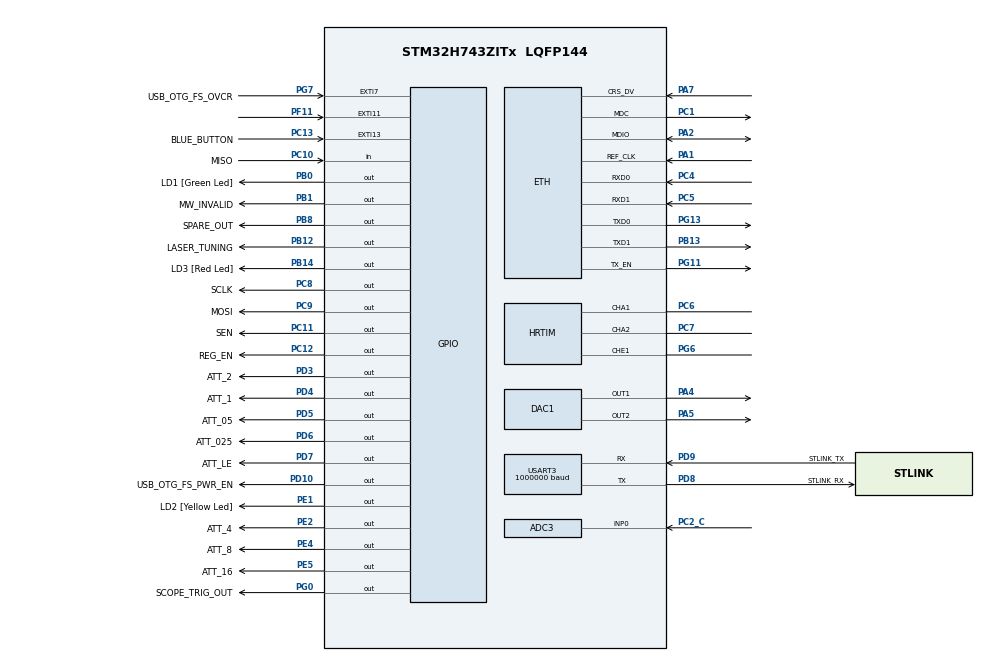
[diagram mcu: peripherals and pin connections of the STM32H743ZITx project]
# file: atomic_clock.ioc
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ADC3.Channel-0\#ChannelRegularConversion=ADC_CHANNEL_0
ADC3.ContinuousConvMode=DISABLE
ADC3.LeftBitShift=ADC_LEFTBITSHIFT_NONE
ADC3.NbrOfConversionFlag=1
ADC3.OffsetNumber-0\#ChannelRegularConversion=ADC_OFFSET_NONE
ADC3.OffsetSignedSaturation-0\#ChannelRegularConversion=DISABLE
ADC3.Rank-0\#ChannelRegularConversion=1
ADC3.SamplingTime-0\#ChannelRegularConversion=ADC_SAMPLETIME_1CYCLE_5
CORTEX_M7.AccessPermission-Cortex_Memory_Protection_Unit_Region1_Settings=MPU_REGION_FULL_ACCESS
CORTEX_M7.AccessPermission-Cortex_Memory_Protection_Unit_Region2_Settings=MPU_REGION_FULL_ACCESS
CORTEX_M7.BaseAddress-Cortex_Memory_Protection_Unit_Region1_Settings=0x30020000
CORTEX_M7.BaseAddress-Cortex_Memory_Protection_Unit_Region2_Settings=0x30040000
CORTEX_M7.CPU_DCache=Enabled
CORTEX_M7.CPU_ICache=Enabled
CORTEX_M7.DisableExec-Cortex_Memory_Protection_Unit_Region0_Settings=MPU_INSTRUCTION_ACCESS_DISABLE
CORTEX_M7.DisableExec-Cortex_Memory_Protection_Unit_Region1_Settings=MPU_INSTRUCTION_ACCESS_DISABLE
CORTEX_M7.DisableExec-Cortex_Memory_Protection_Unit_Region2_Settings=MPU_INSTRUCTION_ACCESS_DISABLE
CORTEX_M7.Enable-Cortex_Memory_Protection_Unit_Region0_Settings=MPU_REGION_ENABLE
CORTEX_M7.Enable-Cortex_Memory_Protection_Unit_Region1_Settings=MPU_REGION_ENABLE
CORTEX_M7.Enable-Cortex_Memory_Protection_Unit_Region2_Settings=MPU_REGION_ENABLE
CORTEX_M7.IsBufferable-Cortex_Memory_Protection_Unit_Region2_Settings=MPU_ACCESS_BUFFERABLE
CORTEX_M7.IsShareable-Cortex_Memory_Protection_Unit_Region0_Settings=MPU_ACCESS_SHAREABLE
CORTEX_M7.IsShareable-Cortex_Memory_Protection_Unit_Region2_Settings=MPU_ACCESS_SHAREABLE
CORTEX_M7.MPU_Control=MPU_PRIVILEGED_DEFAULT
CORTEX_M7.Size-Cortex_Memory_Protection_Unit_Region0_Settings=MPU_REGION_SIZE_4GB
CORTEX_M7.Size-Cortex_Memory_Protection_Unit_Region1_Settings=MPU_REGION_SIZE_128KB
CORTEX_M7.Size-Cortex_Memory_Protection_Unit_Region2_Settings=MPU_REGION_SIZE_512B
CORTEX_M7.SubRegionDisable-Cortex_Memory_Protection_Unit_Region0_Settings=0x87
CORTEX_M7.TypeExtField-Cortex_Memory_Protection_Unit_Region1_Settings=MPU_TEX_LEVEL1
CORTEX_M7.default_mode_Activation=0
DAC1.DAC_Channel-DAC_OUT1=DAC_CHANNEL_1
DAC1.DAC_Channel-DAC_OUT2=DAC_CHANNEL_2
ETH.MediaInterface=HAL_ETH_RMII_MODE
HRTIM.CompareUnit1-Output_TA1TA2=HRTIM_COMPAREUNIT_1
HRTIM.CompareUnit1-Output_TE1=HRTIM_COMPAREUNIT_1
HRTIM.CompareUnit2-Output_TA1TA2=HRTIM_COMPAREUNIT_2
HRTIM.CompareUnit2-Output_TE1=HRTIM_COMPAREUNIT_2
HRTIM.CompareUnit3-Output_TA1TA2=HRTIM_COMPAREUNIT_3
HRTIM.CompareUnit3-Output_TE1=HRTIM_COMPAREUNIT_3
HRTIM.CompareUnit4-Output_TE1=HRTIM_COMPAREUNIT_4
HRTIM.CompareValue1-Output_TA1TA2=PUMP_WIDTH
HRTIM.CompareValue1-Output_TE1=PUMP_WIDTH+MICROWAVE_DELAY
HRTIM.CompareValue2-Output_TA1TA2=PUMP_WIDTH+(2*MICROWAVE_DELAY)+(2*MICROWAVE_WIDTH)+RAMSEY_TIME
HRTIM.CompareValue2-Output_TE1=PUMP_WIDTH+MICROWAVE_DELAY+MICROWAVE_WIDTH
HRTIM.CompareValue3-Output_TA1TA2=PUMP_WIDTH+(2*MICROWAVE_DELAY)+(2*MICROWAVE_WIDTH)+RAMSEY_TIME+PROBE_WIDTH
HRTIM.CompareValue3-Output_TE1=PUMP_WIDTH+MICROWAVE_DELAY+MICROWAVE_WIDTH+RAMSEY_TIME
HRTIM.CompareValue4-Output_TE1=PUMP_WIDTH+MICROWAVE_DELAY+MICROWAVE_WIDTH+RAMSEY_TIME+MICROWAVE_WIDTH
HRTIM.IdleLevel1-Output_TA1TA2=HRTIM_OUTPUTIDLELEVEL_ACTIVE
HRTIM.IdleLevel2-Output_TA1TA2=HRTIM_OUTPUTIDLELEVEL_ACTIVE
HRTIM.InterruptRequests1-Output_TA1TA2=HRTIM_TIM_IT_CMP3
HRTIM.InterruptRequests1-Output_TE1=HRTIM_TIM_IT_CMP2
HRTIM.InterruptRequests2-Output_TA1TA2=HRTIM_TIM_IT_REP
HRTIM.InterruptRequests2-Output_TE1=HRTIM_TIM_IT_CMP3
HRTIM.ModeTimeBase-Output_TE1=HRTIM_MODE_CONTINUOUS
HRTIM.NumberInterruptRequests-Output_TA1TA2=2
HRTIM.NumberInterruptRequests-Output_TE1=2
HRTIM.NumberResetSource1-Output_TA1TA2=2
HRTIM.NumberResetSource1-Output_TE1=2
HRTIM.NumberResetSource2_TA=1
HRTIM.NumberSetSource1-Output_TA1TA2=2
HRTIM.NumberSetSource1-Output_TE1=2
HRTIM.NumberSetSource2_TA=1
HRTIM.Periode_TA=PUMP_WIDTH+(2*MICROWAVE_DELAY)+(2*MICROWAVE_WIDTH)+RAMSEY_TIME+PROBE_WIDTH+POP_CYCLE_DELAY
HRTIM.Periode_TE=PUMP_WIDTH+(2*MICROWAVE_DELAY)+(2*MICROWAVE_WIDTH)+RAMSEY_TIME+PROBE_WIDTH+POP_CYCLE_DELAY
HRTIM.Polarity1-Output_TA1TA2=HRTIM_OUTPUTPOLARITY_LOW
HRTIM.Polarity2-Output_TA1TA2=HRTIM_OUTPUTPOLARITY_LOW
HRTIM.PrescalerRatio_TA=HRTIM_PRESCALERRATIO_DIV4
HRTIM.PrescalerRatio_TE=HRTIM_PRESCALERRATIO_DIV4
HRTIM.ResetOutput1_Source1-Output_TA1TA2=HRTIM_OUTPUTRESET_TIMCMP2
HRTIM.ResetOutput1_Source1-Output_TE1=HRTIM_OUTPUTRESET_TIMCMP2
HRTIM.ResetOutput1_Source2-Output_TA1TA2=HRTIM_OUTPUTRESET_TIMPER
HRTIM.ResetOutput1_Source2-Output_TE1=HRTIM_OUTPUTRESET_TIMCMP4
HRTIM.ResetOutput2_Source1-Output_TA1TA2=HRTIM_OUTPUTRESET_TIMCMP2
HRTIM.SetOutput1_Source1-Output_TA1TA2=HRTIM_OUTPUTSET_TIMCMP1
HRTIM.SetOutput1_Source1-Output_TE1=HRTIM_OUTPUTSET_TIMCMP1
HRTIM.SetOutput1_Source2-Output_TA1TA2=HRTIM_OUTPUTSET_TIMCMP3
HRTIM.SetOutput1_Source2-Output_TE1=HRTIM_OUTPUTSET_TIMCMP3
HRTIM.SetOutput2_Source1-Output_TA1TA2=HRTIM_OUTPUTSET_TIMCMP3
HRTIM.SyncOptions=HRTIM_SYNCOPTION_NONE
LPTIM1.ClockPrescaler=LPTIM_PRESCALER_DIV32
LWIP.BSP.number=1
LWIP.GATEWAY_ADDRESS=192.168.001.001
LWIP.IP_ADDRESS=192.168.001.010
LWIP.LWIP_DHCP=0
LWIP.LWIP_RAM_HEAP_POINTER=0x30020000
LWIP.MEM_SIZE=131048
LWIP.NETMASK_ADDRESS=255.255.000.000
LWIP.TCP_MSS=1460
LWIP.TCP_SND_BUF=5840
LWIP.TCP_SND_QUEUELEN=16
LWIP.Version=v2.1.2_Cube
LWIP0.BSP.STBoard=false
LWIP0.BSP.api=BSP_COMPONENT_DRIVER
LWIP0.BSP.component=LAN8742
LWIP0.BSP.instance=LAN8742
LWIP0.BSP.name=Driver_PHY
LWIP0.BSP.semaphore=S_LAN8742
LWIP0.BSP.solution=LAN8742
Mcu.Family=STM32H7
Mcu.Name=STM32H743ZITx
Mcu.Package=LQFP144
Mcu.UserConstants=POP_CYCLE_DELAY,31250;MICROWAVE_WIDTH,1563;PROBE_WIDTH,625;MICROWAVE_DELAY,312;PUMP_WIDTH,1563;RAMSEY_TIME,12500
NVIC.ADC3_IRQn=true\:0\:0\:false\:false\:true\:true\:true\:true
NVIC.EXTI15_10_IRQn=true\:0\:0\:false\:false\:true\:true\:true\:true
NVIC.HRTIM1_TIMA_IRQn=true\:0\:0\:true\:false\:true\:true\:true\:true
NVIC.HRTIM1_TIME_IRQn=true\:0\:0\:false\:false\:true\:true\:true\:true
NVIC.LPTIM1_IRQn=true\:0\:0\:true\:false\:true\:true\:true\:true
NVIC.PriorityGroup=NVIC_PRIORITYGROUP_4
PA1.Mode=RMII
PA1.Signal=ETH_REF_CLK
PA11.Signal=USB_OTG_FS_DM
PA12.Signal=USB_OTG_FS_DP
PA2.Mode=RMII
PA2.Signal=ETH_MDIO
PA4.Signal=COMP_DAC11_group
PA5.Signal=COMP_DAC12_group
PA7.Mode=RMII
PA7.Signal=ETH_CRS_DV
PA8.Signal=USB_OTG_FS_SOF
PA9.Signal=USB_OTG_FS_VBUS
PB0.GPIO_Label=LD1 [Green Led]
PB0.Signal=GPIO_Output
PB1.GPIO_Label=MW_INVALID
PB1.Signal=GPIO_Output
PB12.GPIO_Label=LASER_TUNING
PB12.Signal=GPIO_Output
PB13.Mode=RMII
PB13.Signal=ETH_TXD1
PB14.GPIO_Label=LD3 [Red Led]
PB14.Signal=GPIO_Output
PB8.GPIO_Label=SPARE_OUT
PB8.Signal=GPIO_Output
PC1.Mode=RMII
PC1.Signal=ETH_MDC
PC10.GPIO_Label=MISO
PC10.GPIO_PuPd=GPIO_NOPULL
PC10.Signal=GPIO_Input
PC11.GPIO_Label=SEN
PC11.GPIO_PuPd=GPIO_PULLDOWN
PC11.PinState=GPIO_PIN_SET
PC11.Signal=GPIO_Output
PC12.GPIO_Label=REG_EN
PC12.GPIO_PuPd=GPIO_PULLDOWN
PC12.Signal=GPIO_Output
PC13.GPIO_Label=BLUE_BUTTON
PC13.GPIO_ModeDefaultEXTI=GPIO_MODE_IT_RISING
PC13.Signal=GPXTI13
PC14-OSC32_IN\ (OSC32_IN).Mode=LSE-External-Oscillator
PC14-OSC32_IN\ (OSC32_IN).Signal=RCC_OSC32_IN
PC15-OSC32_OUT\ (OSC32_OUT).Mode=LSE-External-Oscillator
PC15-OSC32_OUT\ (OSC32_OUT).Signal=RCC_OSC32_OUT
PC2_C.Mode=IN0-Single-Ended
PC2_C.Signal=ADC3_INP0
PC4.Mode=RMII
PC4.Signal=ETH_RXD0
PC5.Mode=RMII
PC5.Signal=ETH_RXD1
PC6.GPIO_PuPd=GPIO_NOPULL
PC6.GPIO_Speed_High_Default=GPIO_SPEED_FREQ_VERY_HIGH
PC6.Mode=Output_TA1TA2
PC6.Signal=HRTIM_CHA1
PC7.Mode=Output_TA1TA2
PC7.Signal=HRTIM_CHA2
PC8.GPIO_Label=SCLK
PC8.GPIO_PuPd=GPIO_PULLDOWN
PC8.Signal=GPIO_Output
PC9.GPIO_Label=MOSI
PC9.GPIO_PuPd=GPIO_PULLDOWN
PC9.Signal=GPIO_Output
PD10.GPIO_Label=USB_OTG_FS_PWR_EN
PD10.Signal=GPIO_Output
PD3.GPIO_Label=ATT_2
PD3.PinState=GPIO_PIN_SET
PD3.Signal=GPIO_Output
PD4.GPIO_Label=ATT_1
PD4.PinState=GPIO_PIN_SET
PD4.Signal=GPIO_Output
PD5.GPIO_Label=ATT_05
PD5.PinState=GPIO_PIN_SET
PD5.Signal=GPIO_Output
PD6.GPIO_Label=ATT_025
PD6.PinState=GPIO_PIN_SET
PD6.Signal=GPIO_Output
PD7.GPIO_Label=ATT_LE
PD7.PinState=GPIO_PIN_SET
PD7.Signal=GPIO_Output
PD8.GPIO_Label=STLINK_RX
PD8.Mode=Asynchronous
PD8.Signal=USART3_TX
PD9.GPIO_Label=STLINK_TX
PD9.Mode=Asynchronous
PD9.Signal=USART3_RX
PE1.GPIO_Label=LD2 [Yellow Led]
PE1.PinAttribute=Free
PE1.Signal=GPIO_Output
PE2.GPIO_Label=ATT_4
PE2.PinState=GPIO_PIN_SET
PE2.Signal=GPIO_Output
PE4.GPIO_Label=ATT_8
PE4.PinState=GPIO_PIN_SET
PE4.Signal=GPIO_Output
PE5.GPIO_Label=ATT_16
PE5.PinState=GPIO_PIN_SET
PE5.Signal=GPIO_Output
PF11.Signal=GPXTI11
PG0.GPIO_Label=SCOPE_TRIG_OUT
PG0.Signal=GPIO_Output
PG11.Mode=RMII
PG11.Signal=ETH_TX_EN
PG13.Mode=RMII
PG13.Signal=ETH_TXD0
PG6.GPIO_PuPd=GPIO_NOPULL
PG6.GPIO_Speed_High_Default=GPIO_SPEED_FREQ_VERY_HIGH
PG6.Mode=Output_TE1
PG6.Signal=HRTIM_CHE1
PG7.GPIO_Label=USB_OTG_FS_OVCR
PG7.Signal=GPXTI7
PH0-OSC_IN\ (PH0).Mode=HSE-External-Clock-Source
PH0-OSC_IN\ (PH0).Signal=RCC_OSC_IN
PH1-OSC_OUT\ (PH1).Signal=RCC_OSC_OUT
ProjectManager.HeapSize=0x200
ProjectManager.StackSize=0x400
ProjectManager.TargetToolchain=STM32CubeIDE
RCC.ADCFreq_Value=2405063.2911392404
RCC.APB1Freq_Value=100000000
RCC.APB2Freq_Value=6250000
RCC.APB3Freq_Value=100000000
RCC.APB4Freq_Value=100000000
RCC.CKPERSourceSelection=RCC_CLKPSOURCE_HSE
RCC.CSICalibrationValue=16
RCC.CortexFreq_Value=400000000
RCC.D2PPRE2=RCC_APB2_DIV16
RCC.DIVM1=1
RCC.DIVM2=1
RCC.DIVN1=80
RCC.DIVN2=19
RCC.DIVP2=79
RCC.DIVQ1=4
RCC.EnbaleCSS=true
RCC.FLatency-AdvancedSettings=FLASH_LATENCY_0
RCC.HCLKFreq_Value=100000000
RCC.HPRE=RCC_HCLK_DIV4
RCC.HSE_VALUE=10000000
RCC.HSICalibrationValue=32
RCC.LPTIM1CLockSelection=RCC_LPTIM1CLKSOURCE_LSE
RCC.LPTIM2CLockSelection=RCC_LPTIM2CLKSOURCE_LSE
RCC.PLL1_VCI_Range-AdvancedSettings=RCC_PLL1VCIRANGE_0
RCC.PLL1_VCO_SEL=RCC_PLL1VCOWIDE
RCC.PLL2FRACN=0
RCC.PLL2_VCI_Range-AdvancedSettings=RCC_PLL2VCIRANGE_0
RCC.PLL2_VCO_SEL-AdvancedSettings=RCC_PLL2VCOMEDIUM
RCC.PLL3FRACN=0
RCC.PLL3_VCI_Range-AdvancedSettings=RCC_PLL3VCIRANGE_0
RCC.PLL3_VCO_SEL-AdvancedSettings=RCC_PLL3VCOMEDIUM
RCC.PLLFRACN=0
RCC.PLLSourceVirtual=RCC_PLLSOURCE_HSE
RCC.PWR_Regulator_Voltage_Scale=PWR_REGULATOR_VOLTAGE_SCALE1
RCC.ProductRev=revV
RCC.SYSCLKFreq_VALUE=400000000
RCC.SYSCLKSource=RCC_SYSCLKSOURCE_PLLCLK
RCC.USBFreq_Value=200000000
SH.COMP_DAC11_group.0=DAC1_OUT1,DAC_OUT1
SH.COMP_DAC12_group.0=DAC1_OUT2,DAC_OUT2
TIM1.Prescaler=1249
TIM2.Prescaler=124
TIM3.Prescaler=124
TIM4.Prescaler=62499
TIM5.Prescaler=124
USART3.BaudRate=1000000
USART3.VirtualMode-Asynchronous=VM_ASYNC
VP_LPTIM1_VS_LPTIM_counterModeInternalClock.Mode=Counts__internal_clock_event_00
VP_LWIP_VS_Enabled.Mode=Enabled
VP_RCC_LSE.Mode=CRS SYNC Source LSE
VP_TIM1_VS_ClockSourceINT.Mode=Internal
VP_TIM2_VS_ClockSourceINT.Mode=Internal
VP_TIM3_VS_ClockSourceINT.Mode=Internal
VP_TIM4_VS_ClockSourceINT.Mode=Internal
VP_TIM5_VS_ClockSourceINT.Mode=Internal
board=NUCLEO-H743ZI2

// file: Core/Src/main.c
/* USER CODE BEGIN Header */
/**
 ******************************************************************************
 * @file           : main.c
 * @brief          : Main program body
 * @authors		   : Simon J. Bale and Stuart Kenny
 ******************************************************************************
 */
/* USER CODE END Header */
#include "main.h"
#include "lwip.h"

/* USER CODE BEGIN Includes */
#include "mw_gen.h"
//#include "laserlock.h"
#include <stdio.h>
#include <stdint.h>
#include <stdbool.h>
#include <string.h>
#include <math.h>

/* USER CODE END Includes */

/* USER CODE BEGIN PTD */
#ifdef ETHERNET_FOR_LDC501
extern struct netif gnetif;
#endif //ETHERNET_FOR_LDC501

/* USER CODE END PTD */

/* USER CODE BEGIN PD */

#define PUTCHAR_PROTOTYPE int __io_putchar(int ch)
//#define ETHERNET_FOR_LDC501
#define SYNTH_ENABLE
#define POP_START_PULSE
//#define QUANTIFY_ADC_NOISE
#define MW_VERBOSE
#define NO_SCOPE_SYNC 0
#define ADD_SCOPE_SYNC_TIME 0
#define DIRECT_ADC_TO_DAC

/* USER CODE END PD */

ADC_HandleTypeDef hadc3;

DAC_HandleTypeDef hdac1;

HRTIM_HandleTypeDef hhrtim;

LPTIM_HandleTypeDef hlptim1;

TIM_HandleTypeDef htim1;
TIM_HandleTypeDef htim2;
TIM_HandleTypeDef htim3;
TIM_HandleTypeDef htim4;
TIM_HandleTypeDef htim5;

UART_HandleTypeDef huart3;

/* USER CODE BEGIN PV */
static const uint32_t ERROR_LED_DELAY = 1000; // 100 ms

//extern SweepSettings const sweep_settings;
extern bool absorption_dip_locked;

extern uint32_t _siitcm;
extern uint32_t _sitcm;
extern uint32_t _eitcm;

static volatile bool mw_sweep_started = false;
volatile bool blue_button_status; //blue button state. 1 when pressed
//static bool last_pin_status; //previous blue button state
volatile uint16_t sample_count=0; //counts number of times the sample line drives the ADC trigger high, updated after conversion is complete
uint32_t POP_period_us=0; //length of POP cycle in us

static uint8_t MW_power = 0x2; // Initial MW power i.e. LO2GAIN
//3 is max, 0 is min, log scale with 2dB between points
//max is +5dBm output, min is -1dBm out.
//NOTE - these values are measured and not consistent with datasheet

/* ADC sample storage */
uint32_t adc_val, adc_averaged_val; //used to store adc3 readings (16-bit value in a 32-bit reg)
uint32_t adc_readings[ADC_SAMPLES]; //an array for the requisite number of samples
uint16_t adc_sample_no = 0; //for storing a rotating pointer to the array
uint32_t adc_readings_total = 0; //for storing the total of N samples
bool adc_average_updated = false; //allows polling without needing to compare previous values
uint32_t adc_polled_above = 0; //used to store adc3 readings
uint32_t adc_polled_below = 0; //used to store adc3 readings
#ifdef QUANTIFY_ADC_NOISE
uint32_t adc_raw_max, adc_raw_min; //used to store adc3 readings
#endif //QUANTIFY_ADC_NOISE
uint32_t adc_averaged_max, adc_averaged_min; //used to store adc3 readings
uint32_t dac_val; //for dac1 output channel 1

//const double HYPERFINE = 3035736939; //Rb85 hyperfine frequency
////static const double MW_DELTA = -1817; //MW offset
//static const double MW_DELTA = 1000; //MW offset

#ifdef ETHERNET_FOR_LDC501
double ild = 160; //laser diode current, 160mA initial value
#endif //ETHERNET_FOR_LDC501

/* USER CODE END PV */

void SystemClock_Config(void);
static void MPU_Config(void);
static void MX_GPIO_Init(void);
static void MX_LPTIM1_Init(void);
static void MX_DAC1_Init(void);
static void MX_USART3_UART_Init(void);
static void MX_TIM3_Init(void);
static void MX_TIM1_Init(void);
static void MX_HRTIM_Init(void);
static void MX_ADC3_Init(void);
static void MX_TIM2_Init(void);
static void MX_TIM5_Init(void);
static void MX_TIM4_Init(void);
/* USER CODE BEGIN PFP */

/* TIMER functions */
extern void timer_delay(TIM_TypeDef *timer, uint32_t delay_us);
extern uint32_t start_timer(TIM_TypeDef * timer);
extern uint32_t stop_timer(TIM_TypeDef * timer);
extern uint32_t check_timer(TIM_TypeDef *timer);

/* MW functions */
extern uint32_t set_MW_power (const uint8_t mw_power);
extern uint32_t init_synthesiser(const uint8_t mw_power);
extern void set_frequency_hz(const double fo);
extern void run_sweep(void);
extern void MW_frequency_toggle (const double f_one, const double f_two);
extern void test_call(void);
extern bool calc_defined_step_MW_sweep(const double centre_freq, const double span, const uint32_t pop_cycles_per_step, const uint32_t num_points_req);
extern bool calc_fixed_time_MW_sweep(const double centre_freq, const double span, const double requested_sweep_period, const bool scope_sync_time);
extern void stop_MW_operation(void);
extern const bool MW_update(void);
extern void start_POP_cycle_calibration(const bool cal_only);
extern void start_continuous_MW_sweep(void);
//extern uint32_t measure_POP_cycle(void);
//extern void initiate_MW_calibration_sweep(const uint32_t POP_period_us);
__attribute__((section(".itcm"))) void measure_POP_cycle_time (void);
__attribute__((section(".itcm"))) void system_mode_MW (void);

/* LASER control functions */
extern void start_laser_tuning(void);
extern void start_laser_ramp(void);
extern void stop_laser_tuning(void);
extern const bool laser_update(void);
__attribute__((section(".itcm"))) void system_mode_laser_tuning (void);

/* ADC functions */
__attribute__((section(".itcm"))) void reset_adc_samples(void);

/* Simon's dodgy functions */
//extern static void start_pop();
//extern static void stop_pop();

#ifdef ETHERNET_FOR_LDC501
/* Telnet prototypes*/
extern bool telnet_client_init(void);
extern void one_off (void);
extern bool init_ldc_comms(void);
extern bool init_ldc_tec(void);
extern void set_laser_current(const double i);
extern bool set_laser_state(bool laserstate);
#endif //ETHERNET_FOR_LDC501

/* USER CODE END PFP */

/* USER CODE BEGIN 0 */

/**
  * @brief  Retargets the C library printf function to the USART.
  * @param  None
  * @retval None
  */
PUTCHAR_PROTOTYPE {
	HAL_UART_Transmit(&huart3, (uint8_t*) &ch, 1, 0xFFFF);
	return ch;
}

/* USER CODE END 0 */

int main(void)
{
  /* USER CODE BEGIN 1 */

  /* Copy from FLASH to itcm */
  memcpy(&_sitcm, &_siitcm, ((void*) &_eitcm - (void*) &_sitcm));

  /* USER CODE END 1 */

  /* MPU Configuration--------------------------------------------------------*/
  MPU_Config();
/* Enable the CPU Cache */

  /* Enable I-Cache---------------------------------------------------------*/
  SCB_EnableICache();

  /* Enable D-Cache---------------------------------------------------------*/
  SCB_EnableDCache();

  /* MCU Configuration--------------------------------------------------------*/

  /* Reset of all peripherals, Initializes the Flash interface and the Systick. */
  HAL_Init();

  /* Configure the system clock */
  SystemClock_Config();

  /* Initialize all configured peripherals */
  MX_GPIO_Init();
  MX_LPTIM1_Init();
  MX_DAC1_Init();
  MX_USART3_UART_Init();
  MX_TIM3_Init();
  MX_TIM1_Init();
  MX_HRTIM_Init();
  MX_ADC3_Init();
  MX_LWIP_Init();
  MX_TIM2_Init();
  MX_TIM5_Init();
  MX_TIM4_Init();
  /* USER CODE BEGIN 2 */
  printf("\033c"); //clears screen
  printf("Atomic Clock - Source __TIMESTAMP__: %s\r\n", __TIMESTAMP__);

	#ifdef SYNTH_ENABLE
		if (init_synthesiser(MW_power) != SUCCESS) {
			printf("Synthesiser initialisation failed!\r\n");
			Error_Handler();
		}
		#ifdef MW_VERBOSE
			printf("MW power setting (LO2GAIN): 0x%x \r\n", MW_power);
		#endif	//MW_VERBOSE
	#else //SYNTH_ENABLE
		printf("WARNING - MW Synthesiser is disabled\r\n");
	#endif //SYNTH_ENABLE

	/* Start a low power timer to flash an LED approximately every second */
	if (HAL_LPTIM_Counter_Start_IT(&hlptim1, 1024) != HAL_OK) {
		printf("Failed to start slow flashing LED!\r\n");
		Error_Handler();
	}

	/* Start the DAC and zero its outputs */
	if (HAL_DAC_Start(&hdac1, DAC_CHANNEL_1) != HAL_OK) {
		printf("Failure to initialise DAC channel 1 \r\n");
		Error_Handler();
	}
	if (HAL_DAC_Start(&hdac1, DAC_CHANNEL_2) != HAL_OK) {
		printf("Failure to initialise DAC channel 2 \r\n");
		Error_Handler();
	}
	/* DAC values are 1241 steps per Volt. Range of 0 to 4095 */
	printf("Setting DAC output 1 (OCXO control) to 0V \r\n");
	if(HAL_DAC_SetValue(&hdac1, DAC_CHANNEL_1, DAC_ALIGN_12B_R, 0) != HAL_OK){
			printf("DAC setup failed for channel 1!\r\n");
		Error_Handler();
	}
	printf("Setting DAC output 2 (laser control) to 0V \r\n");
	if(HAL_DAC_SetValue(&hdac1, DAC_CHANNEL_2, DAC_ALIGN_12B_R, 0) != HAL_OK){
			printf("DAC setup failed for channel 2!\r\n");
		Error_Handler();
	}

//	HAL_GPIO_WritePin(LASER_TUNING_GPIO_Port, LASER_TUNING_Pin, GPIO_PIN_SET); // Laser_tuning output high
//	//MW_invalid low to ensure sample pulse is generated - not strictly needed in FPGA state 0

	/* Fire up the ADC
	 * external trigger, single conversion selected in .ioc file
	 * calibrate ADC for better accuracy and start it w/ interrupt
	 */
	if(HAL_ADCEx_Calibration_Start(&hadc3, ADC_CALIB_OFFSET, ADC_SINGLE_ENDED) != HAL_OK){
		printf("ADC calibration failure \r\n");
		Error_Handler();
	}
	if (pow(2,ADC_SAMPLE_POWER) != ADC_SAMPLES) {
		printf("ADC sampling constants incorrectly initialised \r\n");
		printf("2 ^ ADC_SAMPLE_POWER (%u) does not equal ADC_SAMPLES (%u)\r\n", ADC_SAMPLE_POWER, ADC_SAMPLES);
		Error_Handler();
	}
	//Start the ADC with interrupts enabled
	if(HAL_ADC_Start_IT(&hadc3) != HAL_OK){
		printf("Failed to start ADC with interrupt capability \r\n");
	                Error_Handler();
	}
	printf("ADC calibrated successfully and interrupt callback enabled \r\n");
	#ifdef QUANTIFY_ADC_NOISE
		adc_raw_max = 0;
		adc_averaged_max = 0;
		adc_averaged_min = 0xFFFF;
		adc_raw_min = 0xFFFF;
	#endif //QUANTIFY_ADC_NOISE

	/* Measure the POP cycle time *AFTER* the ADC has been initialised
	 * then calculate sweep settings after first POP calibration routine
	 */
//	HAL_GPIO_WritePin(LASER_TUNING_GPIO_Port, LASER_TUNING_Pin, GPIO_PIN_RESET); // Laser_tuning output low
//	HAL_GPIO_WritePin(MW_INVALID_GPIO_Port, MW_INVALID_Pin, GPIO_PIN_RESET); //Sets MW_invalid pin low
	measure_POP_cycle_time();
	calc_fixed_time_MW_sweep((double)(HYPERFINE + MW_DELTA), 10000, 50, ADD_SCOPE_SYNC_TIME); //10kHz sweep, 50s

//	pin_status = HAL_GPIO_ReadPin(BLUE_BUTTON_GPIO_Port, BLUE_BUTTON_Pin);
//	printf("Blue button status: %u \r\n", pin_status);
//	last_pin_status = pin_status;

//	timer_delay(MW_TIMER, 7000);
//	timer_delay(MW_TIMER, 50000);

#ifdef ETHERNET_FOR_LDC501
	telnet_client_init();
//	bool temp_bool;
//	temp_bool = telnet_client_init(); //initialise telnet client
//	if(!temp_bool) {
//	if(!telnet_client_init()) {
//		printf("Failed to send telnet connection request \r\n");
//	                Error_Handler();
//	}
//	printf("Telnet_client_init returns: %i\r\n", temp_bool);
	printf("Telnet connection request sent and callbacks enabled\r\n");

	init_ldc_comms();
	if(!init_ldc_comms()) { //initialise comms with LDC501
		printf("Failed to initialise comms with LDC501\r\n");
	                Error_Handler();
	}
	printf("Comms established with LDC501\r\n");

	if(!init_ldc_tec() != ERR_OK) { //fire up TEC
		printf("Failed to turn on TEC\r\n");
	                Error_Handler();
	}
	printf("Laser TEC enabled\r\n");

	set_laser_current(ild);
	ild = 171.45678;
	set_laser_current(ild);
	set_laser_state(1);

//	start_timer(SWEEP_TIMER); //reset SWEEP_TIMER and start counting
//	while (!is_telnet_initialised() && (check_timer(SWEEP_TIMER) < 15000000)) {
//		//loop here until telnet is initialised or 15s has elapsed
////		printf("Waiting for telnet to initialise\r\n");
////		printf("Telnet initialisation status %u, SWEEP_TIMER value %lu \r\n", is_telnet_initialised(), check_timer(SWEEP_TIMER));
//	}
//	stop_timer(SWEEP_TIMER); //stop SWEEP_TIMER
//	printf("Telnet initialisation status %u, SWEEP_TIMER value %lu \r\n", is_telnet_initialised(), check_timer(SWEEP_TIMER));

//	printf("Sending test packets\r\n");
//	one_off();
#endif //ETHERNET_FOR_LDC501

	stop_MW_operation();
	start_laser_ramp();
	while(!absorption_dip_locked) {
		laser_update();
	}

  /* USER CODE END 2 */

  /* Infinite loop */
  /* USER CODE BEGIN WHILE */
	printf("Entering main while loop\r\n");
	while (1) {
		//POP can run in SLEEP mode
		//
//		if (!pop_running) {
//			HAL_SuspendTick(); // Needs to be paused or the interrupt will bring us out of STOP mode.
//			HAL_PWREx_EnableFlashPowerDown();
//			HAL_PWR_EnterSTOPMode(PWR_LOWPOWERREGULATOR_ON, PWR_SLEEPENTRY_WFI); // We will only resume when an interrupt occurs
//		} else {
//			HAL_SuspendTick(); // Needs to be paused or the interrupt will bring us out of SLEEP mode.
//			HAL_PWR_EnterSLEEPMode(PWR_MAINREGULATOR_ON, PWR_SLEEPENTRY_WFI); // We will only resume when an interrupt occurs.
//		}

//		pin_status = HAL_GPIO_ReadPin(BLUE_BUTTON_GPIO_Port, BLUE_BUTTON_Pin);
//		if (pin_status != last_pin_status) {
//			printf("Blue button status: %u \r\n", pin_status);
//			last_pin_status = pin_status;
//		}

		blue_button_status = HAL_GPIO_ReadPin(BLUE_BUTTON_GPIO_Port, BLUE_BUTTON_Pin);
		if (blue_button_status) {// If blue button is pressed
			printf("Blue button pressed....\r\n");

			start_laser_ramp();
//			printf("Setting DAC output 2 (laser control) to 3.3V \r\n");
//			if(HAL_DAC_SetValue(&hdac1, DAC_CHANNEL_2, DAC_ALIGN_12B_R, 4095) != HAL_OK){
//					printf("Couldn't set DAC to 3.3V\r\n");
//				Error_Handler();
//			}

#ifdef ETHERNET_FOR_LDC501
			printf("Initialising comms with LDC501\r\n");
			set_laser_state(1);
//			init_ldc_comms();
//			printf("Sending test packets\r\n");
//			one_off(); //send a few test characters to computer
//			HAL_GPIO_WritePin(LASER_TUNING_GPIO_Port, LASER_TUNING_Pin, GPIO_PIN_RESET); // Laser_tuning SMA output low
#endif //ETHERNET_FOR_LDC501

//			/* CODE FOR CHARACTERISING MW GENERATOR FREQUENCY SETTLING TIME */
//			//MW_frequency_toggle (3000000010, 3000010010); //infinite loop toggling between centre of DR dip and 100kHz left of dip
//			//MW_frequency_toggle (3035735189, 3035734189); //infinite loop toggling between centre of DR dip and 1kHz left of dip
//			//MW_frequency_toggle (3035735189, 3035736189); //infinite loop toggling between centre of DR dip and 1 kHz right of dip
//			//set_MW_power(0x03); //set maximum MW power to improve contrast
//			//MW_frequency_toggle (3035733689, 3035733789); //infinite loop toggling 100Hz on left of DR dip
//			//MW_frequency_toggle (3035733689, 3035733699); //infinite loop toggling 10Hz on left of DR dip
//
//			//change the MW power each time the button is pressed, unless it's the first time round this loop
//			if (mw_sweep_started) {
//				++MW_power; //increase MW_power value by 1
//				if (MW_power>3) { //Loop MW_power back round to 0 if above maximum permissible value i.e. 3
//					MW_power = 0;
//				}
//				set_MW_power(MW_power);
//			#ifdef MW_VERBOSE
//				printf("LO2GAIN changed to: 0x%x \r\n", MW_power);
//			#endif //MW_VERBOSE
//			} else {
//				printf("Initiating sweep.\r\n");
//				mw_sweep_started = true;
//				start_continuous_MW_sweep();
//			}
			while(blue_button_status) {//remain here polling button until it is released
				timer_delay(SLOW_TIMER, 100); //1ms delay
				blue_button_status = HAL_GPIO_ReadPin(BLUE_BUTTON_GPIO_Port, BLUE_BUTTON_Pin);
			}
		}

//		if (mw_sweep_started) {//won't execute until the first time the blue button is pressed
//			/* Run the frequency sweep */
////			HAL_GPIO_WritePin(LD3_GPIO_Port, LD3_Pin, GPIO_PIN_SET); //turn on red LED
////			run_sweep();
////			HAL_GPIO_WritePin(LD3_GPIO_Port, LD3_Pin, GPIO_PIN_RESET); //turn off red LED
//			//printf("Sweep complete.\r\n");
//			//printf("LO2GAIN: 0x%x \r\n", MW_power);
//		}
		MW_update();
		laser_update();

#ifdef ETHERNET_FOR_LDC501
	    /* Ethernet handling */
		ethernetif_input(&gnetif);
		sys_check_timeouts();
//		printf("Ethernet loop.\r\n");
#endif //ETHERNET_FOR_LDC501
    /* USER CODE END WHILE */

	}
}

void SystemClock_Config(void)
{
  RCC_OscInitTypeDef RCC_OscInitStruct = {0};
  RCC_ClkInitTypeDef RCC_ClkInitStruct = {0};
  RCC_CRSInitTypeDef RCC_CRSInitStruct = {0};

  /** Supply configuration update enable
  */
  HAL_PWREx_ConfigSupply(PWR_LDO_SUPPLY);

  /** Configure the main internal regulator output voltage
  */
  __HAL_PWR_VOLTAGESCALING_CONFIG(PWR_REGULATOR_VOLTAGE_SCALE1);

  while(!__HAL_PWR_GET_FLAG(PWR_FLAG_VOSRDY)) {}

  /** Configure LSE Drive Capability
  */
  HAL_PWR_EnableBkUpAccess();
  __HAL_RCC_LSEDRIVE_CONFIG(RCC_LSEDRIVE_LOW);

  /** Initializes the RCC Oscillators according to the specified parameters
  * in the RCC_OscInitTypeDef structure.
  */
  RCC_OscInitStruct.OscillatorType = RCC_OSCILLATORTYPE_HSI48|RCC_OSCILLATORTYPE_HSE
                              |RCC_OSCILLATORTYPE_LSE;
  RCC_OscInitStruct.HSEState = RCC_HSE_BYPASS;
  RCC_OscInitStruct.LSEState = RCC_LSE_ON;
  RCC_OscInitStruct.HSI48State = RCC_HSI48_ON;
  RCC_OscInitStruct.PLL.PLLState = RCC_PLL_ON;
  RCC_OscInitStruct.PLL.PLLSource = RCC_PLLSOURCE_HSE;
  RCC_OscInitStruct.PLL.PLLM = 1;
  RCC_OscInitStruct.PLL.PLLN = 80;
  RCC_OscInitStruct.PLL.PLLP = 2;
  RCC_OscInitStruct.PLL.PLLQ = 4;
  RCC_OscInitStruct.PLL.PLLR = 2;
  RCC_OscInitStruct.PLL.PLLRGE = RCC_PLL1VCIRANGE_3;
  RCC_OscInitStruct.PLL.PLLVCOSEL = RCC_PLL1VCOWIDE;
  RCC_OscInitStruct.PLL.PLLFRACN = 0;
  if (HAL_RCC_OscConfig(&RCC_OscInitStruct) != HAL_OK)
  {
    Error_Handler();
  }

  /** Initializes the CPU, AHB and APB buses clocks
  */
  RCC_ClkInitStruct.ClockType = RCC_CLOCKTYPE_HCLK|RCC_CLOCKTYPE_SYSCLK
                              |RCC_CLOCKTYPE_PCLK1|RCC_CLOCKTYPE_PCLK2
                              |RCC_CLOCKTYPE_D3PCLK1|RCC_CLOCKTYPE_D1PCLK1;
  RCC_ClkInitStruct.SYSCLKSource = RCC_SYSCLKSOURCE_PLLCLK;
  RCC_ClkInitStruct.SYSCLKDivider = RCC_SYSCLK_DIV1;
  RCC_ClkInitStruct.AHBCLKDivider = RCC_HCLK_DIV4;
  RCC_ClkInitStruct.APB3CLKDivider = RCC_APB3_DIV1;
  RCC_ClkInitStruct.APB1CLKDivider = RCC_APB1_DIV1;
  RCC_ClkInitStruct.APB2CLKDivider = RCC_APB2_DIV16;
  RCC_ClkInitStruct.APB4CLKDivider = RCC_APB4_DIV1;

  if (HAL_RCC_ClockConfig(&RCC_ClkInitStruct, FLASH_LATENCY_1) != HAL_OK)
  {
    Error_Handler();
  }

  /** Enables the Clock Security System
  */
  HAL_RCC_EnableCSS();

  /** Enable the SYSCFG APB clock
  */
  __HAL_RCC_CRS_CLK_ENABLE();

  /** Configures CRS
  */
  RCC_CRSInitStruct.Prescaler = RCC_CRS_SYNC_DIV1;
  RCC_CRSInitStruct.Source = RCC_CRS_SYNC_SOURCE_LSE;
  RCC_CRSInitStruct.Polarity = RCC_CRS_SYNC_POLARITY_RISING;
  RCC_CRSInitStruct.ReloadValue = __HAL_RCC_CRS_RELOADVALUE_CALCULATE(48000000,32768);
  RCC_CRSInitStruct.ErrorLimitValue = 34;
  RCC_CRSInitStruct.HSI48CalibrationValue = 32;

  HAL_RCCEx_CRSConfig(&RCC_CRSInitStruct);
}

static void MX_ADC3_Init(void)
{

  ADC_ChannelConfTypeDef sConfig = {0};

  /** Common config
  */
  hadc3.Instance = ADC3;
  hadc3.Init.Resolution = ADC_RESOLUTION_16B;
  hadc3.Init.ScanConvMode = ADC_SCAN_DISABLE;
  hadc3.Init.EOCSelection = ADC_EOC_SINGLE_CONV;
  hadc3.Init.LowPowerAutoWait = DISABLE;
  hadc3.Init.ContinuousConvMode = DISABLE;
  hadc3.Init.NbrOfConversion = 1;
  hadc3.Init.DiscontinuousConvMode = DISABLE;
  hadc3.Init.ExternalTrigConv = ADC_EXTERNALTRIG_EXT_IT11;
  hadc3.Init.ExternalTrigConvEdge = ADC_EXTERNALTRIGCONVEDGE_RISING;
  hadc3.Init.ConversionDataManagement = ADC_CONVERSIONDATA_DR;
  hadc3.Init.Overrun = ADC_OVR_DATA_PRESERVED;
  hadc3.Init.LeftBitShift = ADC_LEFTBITSHIFT_NONE;
  hadc3.Init.OversamplingMode = DISABLE;
  if (HAL_ADC_Init(&hadc3) != HAL_OK)
  {
    Error_Handler();
  }

  /** Configure Regular Channel
  */
  sConfig.Channel = ADC_CHANNEL_0;
  sConfig.Rank = ADC_REGULAR_RANK_1;
  sConfig.SamplingTime = ADC_SAMPLETIME_1CYCLE_5;
  sConfig.SingleDiff = ADC_SINGLE_ENDED;
  sConfig.OffsetNumber = ADC_OFFSET_NONE;
  sConfig.Offset = 0;
  sConfig.OffsetSignedSaturation = DISABLE;
  if (HAL_ADC_ConfigChannel(&hadc3, &sConfig) != HAL_OK)
  {
    Error_Handler();
  }

}

static void MX_DAC1_Init(void)
{

  DAC_ChannelConfTypeDef sConfig = {0};

  /** DAC Initialization
  */
  hdac1.Instance = DAC1;
  if (HAL_DAC_Init(&hdac1) != HAL_OK)
  {
    Error_Handler();
  }

  /** DAC channel OUT1 config
  */
  sConfig.DAC_SampleAndHold = DAC_SAMPLEANDHOLD_DISABLE;
  sConfig.DAC_Trigger = DAC_TRIGGER_NONE;
  sConfig.DAC_OutputBuffer = DAC_OUTPUTBUFFER_ENABLE;
  sConfig.DAC_ConnectOnChipPeripheral = DAC_CHIPCONNECT_DISABLE;
  sConfig.DAC_UserTrimming = DAC_TRIMMING_FACTORY;
  if (HAL_DAC_ConfigChannel(&hdac1, &sConfig, DAC_CHANNEL_1) != HAL_OK)
  {
    Error_Handler();
  }

  /** DAC channel OUT2 config
  */
  if (HAL_DAC_ConfigChannel(&hdac1, &sConfig, DAC_CHANNEL_2) != HAL_OK)
  {
    Error_Handler();
  }
  /* USER CODE BEGIN DAC1_Init 2 */
  /** DAC auto-calibration
  */
//  if (HAL_DACEx_SelfCalibrate(&hdac1, &sConfig, DAC_CHANNEL_1) != HAL_OK)
//  {
//    printf("Failed to auto-calibrate DAC \r\n");
//    Error_Handler();
//  }

  /* USER CODE END DAC1_Init 2 */

}

static void MX_HRTIM_Init(void)
{

  HRTIM_TimeBaseCfgTypeDef pTimeBaseCfg = {0};
  HRTIM_TimerCfgTypeDef pTimerCfg = {0};
  HRTIM_CompareCfgTypeDef pCompareCfg = {0};
  HRTIM_OutputCfgTypeDef pOutputCfg = {0};

  hhrtim.Instance = HRTIM1;
  hhrtim.Init.HRTIMInterruptResquests = HRTIM_IT_NONE;
  hhrtim.Init.SyncOptions = HRTIM_SYNCOPTION_NONE;
  if (HAL_HRTIM_Init(&hhrtim) != HAL_OK)
  {
    Error_Handler();
  }
  pTimeBaseCfg.Period = PUMP_WIDTH+(2*MICROWAVE_DELAY)+(2*MICROWAVE_WIDTH)+RAMSEY_TIME+PROBE_WIDTH+POP_CYCLE_DELAY;
  pTimeBaseCfg.RepetitionCounter = 0x00;
  pTimeBaseCfg.PrescalerRatio = HRTIM_PRESCALERRATIO_DIV4;
  pTimeBaseCfg.Mode = HRTIM_MODE_CONTINUOUS;
  if (HAL_HRTIM_TimeBaseConfig(&hhrtim, HRTIM_TIMERINDEX_TIMER_A, &pTimeBaseCfg) != HAL_OK)
  {
    Error_Handler();
  }
  pTimerCfg.InterruptRequests = HRTIM_TIM_IT_CMP3|HRTIM_TIM_IT_REP;
  pTimerCfg.DMARequests = HRTIM_TIM_DMA_NONE;
  pTimerCfg.DMASrcAddress = 0x0000;
  pTimerCfg.DMADstAddress = 0x0000;
  pTimerCfg.DMASize = 0x1;
  pTimerCfg.HalfModeEnable = HRTIM_HALFMODE_DISABLED;
  pTimerCfg.StartOnSync = HRTIM_SYNCSTART_DISABLED;
  pTimerCfg.ResetOnSync = HRTIM_SYNCRESET_DISABLED;
  pTimerCfg.DACSynchro = HRTIM_DACSYNC_NONE;
  pTimerCfg.PreloadEnable = HRTIM_PRELOAD_DISABLED;
  pTimerCfg.UpdateGating = HRTIM_UPDATEGATING_INDEPENDENT;
  pTimerCfg.BurstMode = HRTIM_TIMERBURSTMODE_MAINTAINCLOCK;
  pTimerCfg.RepetitionUpdate = HRTIM_UPDATEONREPETITION_DISABLED;
  pTimerCfg.PushPull = HRTIM_TIMPUSHPULLMODE_DISABLED;
  pTimerCfg.FaultEnable = HRTIM_TIMFAULTENABLE_NONE;
  pTimerCfg.FaultLock = HRTIM_TIMFAULTLOCK_READWRITE;
  pTimerCfg.DeadTimeInsertion = HRTIM_TIMDEADTIMEINSERTION_DISABLED;
  pTimerCfg.DelayedProtectionMode = HRTIM_TIMER_A_B_C_DELAYEDPROTECTION_DISABLED;
  pTimerCfg.UpdateTrigger = HRTIM_TIMUPDATETRIGGER_NONE;
  pTimerCfg.ResetTrigger = HRTIM_TIMRESETTRIGGER_NONE;
  pTimerCfg.ResetUpdate = HRTIM_TIMUPDATEONRESET_DISABLED;
  if (HAL_HRTIM_WaveformTimerConfig(&hhrtim, HRTIM_TIMERINDEX_TIMER_A, &pTimerCfg) != HAL_OK)
  {
    Error_Handler();
  }
  pTimerCfg.InterruptRequests = HRTIM_TIM_IT_CMP2|HRTIM_TIM_IT_CMP3;
  pTimerCfg.DelayedProtectionMode = HRTIM_TIMER_D_E_DELAYEDPROTECTION_DISABLED;
  if (HAL_HRTIM_WaveformTimerConfig(&hhrtim, HRTIM_TIMERINDEX_TIMER_E, &pTimerCfg) != HAL_OK)
  {
    Error_Handler();
  }
  pCompareCfg.CompareValue = PUMP_WIDTH;
  if (HAL_HRTIM_WaveformCompareConfig(&hhrtim, HRTIM_TIMERINDEX_TIMER_A, HRTIM_COMPAREUNIT_1, &pCompareCfg) != HAL_OK)
  {
    Error_Handler();
  }
  pCompareCfg.CompareValue = PUMP_WIDTH+(2*MICROWAVE_DELAY)+(2*MICROWAVE_WIDTH)+RAMSEY_TIME;
  pCompareCfg.AutoDelayedMode = HRTIM_AUTODELAYEDMODE_REGULAR;
  pCompareCfg.AutoDelayedTimeout = 0x0000;

  if (HAL_HRTIM_WaveformCompareConfig(&hhrtim, HRTIM_TIMERINDEX_TIMER_A, HRTIM_COMPAREUNIT_2, &pCompareCfg) != HAL_OK)
  {
    Error_Handler();
  }
  pCompareCfg.CompareValue = PUMP_WIDTH+MICROWAVE_DELAY+MICROWAVE_WIDTH;

  if (HAL_HRTIM_WaveformCompareConfig(&hhrtim, HRTIM_TIMERINDEX_TIMER_E, HRTIM_COMPAREUNIT_2, &pCompareCfg) != HAL_OK)
  {
    Error_Handler();
  }
  pCompareCfg.CompareValue = PUMP_WIDTH+(2*MICROWAVE_DELAY)+(2*MICROWAVE_WIDTH)+RAMSEY_TIME+PROBE_WIDTH;
  if (HAL_HRTIM_WaveformCompareConfig(&hhrtim, HRTIM_TIMERINDEX_TIMER_A, HRTIM_COMPAREUNIT_3, &pCompareCfg) != HAL_OK)
  {
    Error_Handler();
  }
  pCompareCfg.CompareValue = PUMP_WIDTH+MICROWAVE_DELAY+MICROWAVE_WIDTH+RAMSEY_TIME+MICROWAVE_WIDTH;

  if (HAL_HRTIM_WaveformCompareConfig(&hhrtim, HRTIM_TIMERINDEX_TIMER_E, HRTIM_COMPAREUNIT_4, &pCompareCfg) != HAL_OK)
  {
    Error_Handler();
  }
  pOutputCfg.Polarity = HRTIM_OUTPUTPOLARITY_LOW;
  pOutputCfg.SetSource = HRTIM_OUTPUTSET_TIMCMP1|HRTIM_OUTPUTSET_TIMCMP3;
  pOutputCfg.ResetSource = HRTIM_OUTPUTRESET_TIMCMP2|HRTIM_OUTPUTRESET_TIMPER;
  pOutputCfg.IdleMode = HRTIM_OUTPUTIDLEMODE_NONE;
  pOutputCfg.IdleLevel = HRTIM_OUTPUTIDLELEVEL_ACTIVE;
  pOutputCfg.FaultLevel = HRTIM_OUTPUTFAULTLEVEL_NONE;
  pOutputCfg.ChopperModeEnable = HRTIM_OUTPUTCHOPPERMODE_DISABLED;
  pOutputCfg.BurstModeEntryDelayed = HRTIM_OUTPUTBURSTMODEENTRY_REGULAR;
  if (HAL_HRTIM_WaveformOutputConfig(&hhrtim, HRTIM_TIMERINDEX_TIMER_A, HRTIM_OUTPUT_TA1, &pOutputCfg) != HAL_OK)
  {
    Error_Handler();
  }
  pOutputCfg.Polarity = HRTIM_OUTPUTPOLARITY_HIGH;
  pOutputCfg.ResetSource = HRTIM_OUTPUTRESET_TIMCMP2|HRTIM_OUTPUTRESET_TIMCMP4;
  pOutputCfg.IdleLevel = HRTIM_OUTPUTIDLELEVEL_INACTIVE;
  if (HAL_HRTIM_WaveformOutputConfig(&hhrtim, HRTIM_TIMERINDEX_TIMER_E, HRTIM_OUTPUT_TE1, &pOutputCfg) != HAL_OK)
  {
    Error_Handler();
  }
  pOutputCfg.Polarity = HRTIM_OUTPUTPOLARITY_LOW;
  pOutputCfg.SetSource = HRTIM_OUTPUTSET_TIMCMP3;
  pOutputCfg.ResetSource = HRTIM_OUTPUTRESET_TIMCMP2;
  pOutputCfg.IdleLevel = HRTIM_OUTPUTIDLELEVEL_ACTIVE;
  if (HAL_HRTIM_WaveformOutputConfig(&hhrtim, HRTIM_TIMERINDEX_TIMER_A, HRTIM_OUTPUT_TA2, &pOutputCfg) != HAL_OK)
  {
    Error_Handler();
  }
  if (HAL_HRTIM_TimeBaseConfig(&hhrtim, HRTIM_TIMERINDEX_TIMER_E, &pTimeBaseCfg) != HAL_OK)
  {
    Error_Handler();
  }
  pCompareCfg.CompareValue = PUMP_WIDTH+MICROWAVE_DELAY;
  if (HAL_HRTIM_WaveformCompareConfig(&hhrtim, HRTIM_TIMERINDEX_TIMER_E, HRTIM_COMPAREUNIT_1, &pCompareCfg) != HAL_OK)
  {
    Error_Handler();
  }
  pCompareCfg.CompareValue = PUMP_WIDTH+MICROWAVE_DELAY+MICROWAVE_WIDTH+RAMSEY_TIME;
  if (HAL_HRTIM_WaveformCompareConfig(&hhrtim, HRTIM_TIMERINDEX_TIMER_E, HRTIM_COMPAREUNIT_3, &pCompareCfg) != HAL_OK)
  {
    Error_Handler();
  }
  HAL_HRTIM_MspPostInit(&hhrtim);

}

static void MX_LPTIM1_Init(void)
{

  hlptim1.Instance = LPTIM1;
  hlptim1.Init.Clock.Source = LPTIM_CLOCKSOURCE_APBCLOCK_LPOSC;
  hlptim1.Init.Clock.Prescaler = LPTIM_PRESCALER_DIV32;
  hlptim1.Init.Trigger.Source = LPTIM_TRIGSOURCE_SOFTWARE;
  hlptim1.Init.OutputPolarity = LPTIM_OUTPUTPOLARITY_HIGH;
  hlptim1.Init.UpdateMode = LPTIM_UPDATE_IMMEDIATE;
  hlptim1.Init.CounterSource = LPTIM_COUNTERSOURCE_INTERNAL;
  hlptim1.Init.Input1Source = LPTIM_INPUT1SOURCE_GPIO;
  hlptim1.Init.Input2Source = LPTIM_INPUT2SOURCE_GPIO;
  if (HAL_LPTIM_Init(&hlptim1) != HAL_OK)
  {
    Error_Handler();
  }

}

static void MX_TIM1_Init(void)
{

  TIM_ClockConfigTypeDef sClockSourceConfig = {0};
  TIM_MasterConfigTypeDef sMasterConfig = {0};

  htim1.Instance = TIM1;
  htim1.Init.Prescaler = 1249;
  htim1.Init.CounterMode = TIM_COUNTERMODE_UP;
  htim1.Init.Period = 65535;
  htim1.Init.ClockDivision = TIM_CLOCKDIVISION_DIV1;
  htim1.Init.RepetitionCounter = 0;
  htim1.Init.AutoReloadPreload = TIM_AUTORELOAD_PRELOAD_DISABLE;
  if (HAL_TIM_Base_Init(&htim1) != HAL_OK)
  {
    Error_Handler();
  }
  sClockSourceConfig.ClockSource = TIM_CLOCKSOURCE_INTERNAL;
  if (HAL_TIM_ConfigClockSource(&htim1, &sClockSourceConfig) != HAL_OK)
  {
    Error_Handler();
  }
  sMasterConfig.MasterOutputTrigger = TIM_TRGO_RESET;
  sMasterConfig.MasterOutputTrigger2 = TIM_TRGO2_RESET;
  sMasterConfig.MasterSlaveMode = TIM_MASTERSLAVEMODE_DISABLE;
  if (HAL_TIMEx_MasterConfigSynchronization(&htim1, &sMasterConfig) != HAL_OK)
  {
    Error_Handler();
  }

}

static void MX_TIM2_Init(void)
{

  TIM_ClockConfigTypeDef sClockSourceConfig = {0};
  TIM_MasterConfigTypeDef sMasterConfig = {0};

  htim2.Instance = TIM2;
  htim2.Init.Prescaler = 124;
  htim2.Init.CounterMode = TIM_COUNTERMODE_UP;
  htim2.Init.Period = 4294967295;
  htim2.Init.ClockDivision = TIM_CLOCKDIVISION_DIV1;
  htim2.Init.AutoReloadPreload = TIM_AUTORELOAD_PRELOAD_DISABLE;
  if (HAL_TIM_Base_Init(&htim2) != HAL_OK)
  {
    Error_Handler();
  }
  sClockSourceConfig.ClockSource = TIM_CLOCKSOURCE_INTERNAL;
  if (HAL_TIM_ConfigClockSource(&htim2, &sClockSourceConfig) != HAL_OK)
  {
    Error_Handler();
  }
  sMasterConfig.MasterOutputTrigger = TIM_TRGO_RESET;
  sMasterConfig.MasterSlaveMode = TIM_MASTERSLAVEMODE_DISABLE;
  if (HAL_TIMEx_MasterConfigSynchronization(&htim2, &sMasterConfig) != HAL_OK)
  {
    Error_Handler();
  }

}

static void MX_TIM3_Init(void)
{

  TIM_ClockConfigTypeDef sClockSourceConfig = {0};
  TIM_MasterConfigTypeDef sMasterConfig = {0};

  htim3.Instance = TIM3;
  htim3.Init.Prescaler = 124;
  htim3.Init.CounterMode = TIM_COUNTERMODE_UP;
  htim3.Init.Period = 65535;
  htim3.Init.ClockDivision = TIM_CLOCKDIVISION_DIV1;
  htim3.Init.AutoReloadPreload = TIM_AUTORELOAD_PRELOAD_DISABLE;
  if (HAL_TIM_Base_Init(&htim3) != HAL_OK)
  {
    Error_Handler();
  }
  sClockSourceConfig.ClockSource = TIM_CLOCKSOURCE_INTERNAL;
  if (HAL_TIM_ConfigClockSource(&htim3, &sClockSourceConfig) != HAL_OK)
  {
    Error_Handler();
  }
  sMasterConfig.MasterOutputTrigger = TIM_TRGO_RESET;
  sMasterConfig.MasterSlaveMode = TIM_MASTERSLAVEMODE_DISABLE;
  if (HAL_TIMEx_MasterConfigSynchronization(&htim3, &sMasterConfig) != HAL_OK)
  {
    Error_Handler();
  }

}

static void MX_TIM4_Init(void)
{

  TIM_ClockConfigTypeDef sClockSourceConfig = {0};
  TIM_MasterConfigTypeDef sMasterConfig = {0};

  htim4.Instance = TIM4;
  htim4.Init.Prescaler = 62499;
  htim4.Init.CounterMode = TIM_COUNTERMODE_UP;
  htim4.Init.Period = 65535;
  htim4.Init.ClockDivision = TIM_CLOCKDIVISION_DIV1;
  htim4.Init.AutoReloadPreload = TIM_AUTORELOAD_PRELOAD_DISABLE;
  if (HAL_TIM_Base_Init(&htim4) != HAL_OK)
  {
    Error_Handler();
  }
  sClockSourceConfig.ClockSource = TIM_CLOCKSOURCE_INTERNAL;
  if (HAL_TIM_ConfigClockSource(&htim4, &sClockSourceConfig) != HAL_OK)
  {
    Error_Handler();
  }
  sMasterConfig.MasterOutputTrigger = TIM_TRGO_RESET;
  sMasterConfig.MasterSlaveMode = TIM_MASTERSLAVEMODE_DISABLE;
  if (HAL_TIMEx_MasterConfigSynchronization(&htim4, &sMasterConfig) != HAL_OK)
  {
    Error_Handler();
  }

}

static void MX_TIM5_Init(void)
{

  TIM_ClockConfigTypeDef sClockSourceConfig = {0};
  TIM_MasterConfigTypeDef sMasterConfig = {0};

  htim5.Instance = TIM5;
  htim5.Init.Prescaler = 124;
  htim5.Init.CounterMode = TIM_COUNTERMODE_UP;
  htim5.Init.Period = 4294967295;
  htim5.Init.ClockDivision = TIM_CLOCKDIVISION_DIV1;
  htim5.Init.AutoReloadPreload = TIM_AUTORELOAD_PRELOAD_DISABLE;
  if (HAL_TIM_Base_Init(&htim5) != HAL_OK)
  {
    Error_Handler();
  }
  sClockSourceConfig.ClockSource = TIM_CLOCKSOURCE_INTERNAL;
  if (HAL_TIM_ConfigClockSource(&htim5, &sClockSourceConfig) != HAL_OK)
  {
    Error_Handler();
  }
  sMasterConfig.MasterOutputTrigger = TIM_TRGO_RESET;
  sMasterConfig.MasterSlaveMode = TIM_MASTERSLAVEMODE_DISABLE;
  if (HAL_TIMEx_MasterConfigSynchronization(&htim5, &sMasterConfig) != HAL_OK)
  {
    Error_Handler();
  }

}

static void MX_USART3_UART_Init(void)
{

  huart3.Instance = USART3;
  huart3.Init.BaudRate = 1000000;
  huart3.Init.WordLength = UART_WORDLENGTH_8B;
  huart3.Init.StopBits = UART_STOPBITS_1;
  huart3.Init.Parity = UART_PARITY_NONE;
  huart3.Init.Mode = UART_MODE_TX_RX;
  huart3.Init.HwFlowCtl = UART_HWCONTROL_NONE;
  huart3.Init.OverSampling = UART_OVERSAMPLING_16;
  huart3.Init.OneBitSampling = UART_ONE_BIT_SAMPLE_DISABLE;
  huart3.Init.ClockPrescaler = UART_PRESCALER_DIV1;
  huart3.AdvancedInit.AdvFeatureInit = UART_ADVFEATURE_NO_INIT;
  if (HAL_UART_Init(&huart3) != HAL_OK)
  {
    Error_Handler();
  }
  if (HAL_UARTEx_SetTxFifoThreshold(&huart3, UART_TXFIFO_THRESHOLD_1_8) != HAL_OK)
  {
    Error_Handler();
  }
  if (HAL_UARTEx_SetRxFifoThreshold(&huart3, UART_RXFIFO_THRESHOLD_1_8) != HAL_OK)
  {
    Error_Handler();
  }
  if (HAL_UARTEx_DisableFifoMode(&huart3) != HAL_OK)
  {
    Error_Handler();
  }

}

static void MX_GPIO_Init(void)
{
  GPIO_InitTypeDef GPIO_InitStruct = {0};

  /* GPIO Ports Clock Enable */
  __HAL_RCC_GPIOE_CLK_ENABLE();
  __HAL_RCC_GPIOC_CLK_ENABLE();
  __HAL_RCC_GPIOH_CLK_ENABLE();
  __HAL_RCC_GPIOA_CLK_ENABLE();
  __HAL_RCC_GPIOB_CLK_ENABLE();
  __HAL_RCC_GPIOF_CLK_ENABLE();
  __HAL_RCC_GPIOG_CLK_ENABLE();
  __HAL_RCC_GPIOD_CLK_ENABLE();

  /*Configure GPIO pin Output Level */
  HAL_GPIO_WritePin(GPIOE, ATT_4_Pin|ATT_8_Pin|ATT_16_Pin, GPIO_PIN_SET);

  /*Configure GPIO pin Output Level */
  HAL_GPIO_WritePin(GPIOB, LD1_Pin|MW_INVALID_Pin|LASER_TUNING_Pin|LD3_Pin
                          |SPARE_OUT_Pin, GPIO_PIN_RESET);

  /*Configure GPIO pin Output Level */
  HAL_GPIO_WritePin(SCOPE_TRIG_OUT_GPIO_Port, SCOPE_TRIG_OUT_Pin, GPIO_PIN_RESET);

  /*Configure GPIO pin Output Level */
  HAL_GPIO_WritePin(USB_OTG_FS_PWR_EN_GPIO_Port, USB_OTG_FS_PWR_EN_Pin, GPIO_PIN_RESET);

  /*Configure GPIO pin Output Level */
  HAL_GPIO_WritePin(GPIOC, SCLK_Pin|MOSI_Pin|REG_EN_Pin, GPIO_PIN_RESET);

  /*Configure GPIO pin Output Level */
  HAL_GPIO_WritePin(SEN_GPIO_Port, SEN_Pin, GPIO_PIN_SET);

  /*Configure GPIO pin Output Level */
  HAL_GPIO_WritePin(GPIOD, ATT_2_Pin|ATT_1_Pin|ATT_05_Pin|ATT_025_Pin
                          |ATT_LE_Pin, GPIO_PIN_SET);

  /*Configure GPIO pin Output Level */
  HAL_GPIO_WritePin(LD2_GPIO_Port, LD2_Pin, GPIO_PIN_RESET);

  /*Configure GPIO pins : ATT_4_Pin ATT_8_Pin ATT_16_Pin LD2_Pin */
  GPIO_InitStruct.Pin = ATT_4_Pin|ATT_8_Pin|ATT_16_Pin|LD2_Pin;
  GPIO_InitStruct.Mode = GPIO_MODE_OUTPUT_PP;
  GPIO_InitStruct.Pull = GPIO_NOPULL;
  GPIO_InitStruct.Speed = GPIO_SPEED_FREQ_LOW;
  HAL_GPIO_Init(GPIOE, &GPIO_InitStruct);

  /*Configure GPIO pin : BLUE_BUTTON_Pin */
  GPIO_InitStruct.Pin = BLUE_BUTTON_Pin;
  GPIO_InitStruct.Mode = GPIO_MODE_IT_RISING;
  GPIO_InitStruct.Pull = GPIO_NOPULL;
  HAL_GPIO_Init(BLUE_BUTTON_GPIO_Port, &GPIO_InitStruct);

  /*Configure GPIO pins : LD1_Pin MW_INVALID_Pin LASER_TUNING_Pin LD3_Pin
                           SPARE_OUT_Pin */
  GPIO_InitStruct.Pin = LD1_Pin|MW_INVALID_Pin|LASER_TUNING_Pin|LD3_Pin
                          |SPARE_OUT_Pin;
  GPIO_InitStruct.Mode = GPIO_MODE_OUTPUT_PP;
  GPIO_InitStruct.Pull = GPIO_NOPULL;
  GPIO_InitStruct.Speed = GPIO_SPEED_FREQ_LOW;
  HAL_GPIO_Init(GPIOB, &GPIO_InitStruct);

  /*Configure GPIO pin : PF11 */
  GPIO_InitStruct.Pin = GPIO_PIN_11;
  GPIO_InitStruct.Mode = GPIO_MODE_IT_RISING;
  GPIO_InitStruct.Pull = GPIO_NOPULL;
  HAL_GPIO_Init(GPIOF, &GPIO_InitStruct);

  /*Configure GPIO pin : SCOPE_TRIG_OUT_Pin */
  GPIO_InitStruct.Pin = SCOPE_TRIG_OUT_Pin;
  GPIO_InitStruct.Mode = GPIO_MODE_OUTPUT_PP;
  GPIO_InitStruct.Pull = GPIO_NOPULL;
  GPIO_InitStruct.Speed = GPIO_SPEED_FREQ_LOW;
  HAL_GPIO_Init(SCOPE_TRIG_OUT_GPIO_Port, &GPIO_InitStruct);

  /*Configure GPIO pins : USB_OTG_FS_PWR_EN_Pin ATT_2_Pin ATT_1_Pin ATT_05_Pin
                           ATT_025_Pin ATT_LE_Pin */
  GPIO_InitStruct.Pin = USB_OTG_FS_PWR_EN_Pin|ATT_2_Pin|ATT_1_Pin|ATT_05_Pin
                          |ATT_025_Pin|ATT_LE_Pin;
  GPIO_InitStruct.Mode = GPIO_MODE_OUTPUT_PP;
  GPIO_InitStruct.Pull = GPIO_NOPULL;
  GPIO_InitStruct.Speed = GPIO_SPEED_FREQ_LOW;
  HAL_GPIO_Init(GPIOD, &GPIO_InitStruct);

  /*Configure GPIO pin : USB_OTG_FS_OVCR_Pin */
  GPIO_InitStruct.Pin = USB_OTG_FS_OVCR_Pin;
  GPIO_InitStruct.Mode = GPIO_MODE_IT_RISING;
  GPIO_InitStruct.Pull = GPIO_NOPULL;
  HAL_GPIO_Init(USB_OTG_FS_OVCR_GPIO_Port, &GPIO_InitStruct);

  /*Configure GPIO pins : SCLK_Pin MOSI_Pin SEN_Pin REG_EN_Pin */
  GPIO_InitStruct.Pin = SCLK_Pin|MOSI_Pin|SEN_Pin|REG_EN_Pin;
  GPIO_InitStruct.Mode = GPIO_MODE_OUTPUT_PP;
  GPIO_InitStruct.Pull = GPIO_PULLDOWN;
  GPIO_InitStruct.Speed = GPIO_SPEED_FREQ_LOW;
  HAL_GPIO_Init(GPIOC, &GPIO_InitStruct);

  /*Configure GPIO pins : PA8 PA11 PA12 */
  GPIO_InitStruct.Pin = GPIO_PIN_8|GPIO_PIN_11|GPIO_PIN_12;
  GPIO_InitStruct.Mode = GPIO_MODE_AF_PP;
  GPIO_InitStruct.Pull = GPIO_NOPULL;
  GPIO_InitStruct.Speed = GPIO_SPEED_FREQ_LOW;
  GPIO_InitStruct.Alternate = GPIO_AF10_OTG1_FS;
  HAL_GPIO_Init(GPIOA, &GPIO_InitStruct);

  /*Configure GPIO pin : MISO_Pin */
  GPIO_InitStruct.Pin = MISO_Pin;
  GPIO_InitStruct.Mode = GPIO_MODE_INPUT;
  GPIO_InitStruct.Pull = GPIO_NOPULL;
  HAL_GPIO_Init(MISO_GPIO_Port, &GPIO_InitStruct);

  /* EXTI interrupt init*/
  HAL_NVIC_SetPriority(EXTI15_10_IRQn, 0, 0);
  HAL_NVIC_EnableIRQ(EXTI15_10_IRQn);

}

/* USER CODE BEGIN 4 */

/**
  * @brief  Function called when ADC conversion complete. Stores an averaged ADC value
  * Should assume that that there's garbage in the adc_readings array until populated
  * but that the adc_readings_total and adc_sample_no are initialised correctly
  * @param  Pointer to ADC (not currently used internally)
  * @retval None
  */
void HAL_ADC_ConvCpltCallback(ADC_HandleTypeDef *hadc)
{
  adc_val = 0x0000FFFF & HAL_ADC_GetValue(&hadc3); //ensure that only 16 bits are recorded
  //printf("ADC value: %lu \r\n", adc_val);
  sample_count++;
	if (ADC_SAMPLE_POWER == 0) { //no averaging required
	#ifdef QUANTIFY_ADC_NOISE
	  if (adc_val < adc_raw_min) {
		  adc_raw_min = adc_val;
		  printf("ADC reading: %lu, max: %lu, min: %lu \r\n", adc_val, adc_raw_max, adc_raw_min);
	  }
	  if (adc_val > adc_raw_max) {
		  adc_raw_max = adc_val;
		  printf("ADC reading: %lu, max: %lu, min: %lu \r\n", adc_val, adc_raw_max, adc_raw_min);
	  }
	  //printf("ADC reading: %lu, max: %lu, min: %lu \r\n", adc_val, adc_raw_max, adc_raw_min);
	#endif //QUANTIFY_ADC_NOISE
		adc_averaged_val = adc_val;
		adc_average_updated = true;
	} else { //averaging in operation
		adc_readings_total = adc_readings_total + adc_val;
		if (sample_count >= ADC_SAMPLES) {//if the sample buffer is full
			adc_readings_total = adc_readings_total - adc_readings[adc_sample_no]; //subtract the expired value from the total
			adc_averaged_val = adc_readings_total >> ADC_SAMPLE_POWER; //truncate as a cycle-efficient division
			adc_average_updated = true;
		}
		adc_readings[adc_sample_no] = adc_val;
		adc_sample_no++;
		if (adc_sample_no >= ADC_SAMPLES) adc_sample_no = 0; //set back to zero if loop complete
		#ifdef QUANTIFY_ADC_NOISE
		  if (adc_val < adc_raw_min) {
			  adc_raw_min = adc_val;
		  }
		  if (adc_val > adc_raw_max) {
			  adc_raw_max = adc_val;
		  }
		  if (adc_average_updated & (adc_averaged_val < adc_averaged_min)) {
			  adc_averaged_min = adc_averaged_val;
			  printf("%u ADC samples\r\n", ADC_SAMPLES);
			  printf("Raw ADC reading: %lu, max: %lu, min: %lu \r\n", adc_val, adc_raw_max, adc_raw_min);
			  printf("ADC average reading: %lu, max: %lu, min: %lu \r\n", adc_averaged_val, adc_averaged_max, adc_averaged_min);
		  }
		  if (adc_average_updated & (adc_averaged_val > adc_averaged_max)) {
			  adc_averaged_max = adc_averaged_val;
			  printf("%u ADC samples\r\n", ADC_SAMPLES);
			  printf("Raw ADC reading: %lu, max: %lu, min: %lu \r\n", adc_val, adc_raw_max, adc_raw_min);
			  printf("ADC average reading: %lu, max: %lu, min: %lu \r\n", adc_averaged_val, adc_averaged_max, adc_averaged_min);
			}
		#endif //QUANTIFY_ADC_NOISE
	}
	#ifdef DIRECT_ADC_TO_DAC
	if(adc_average_updated) {
		dac_val = adc_averaged_val >> 4;
		//printf("ADC value: %lu, DAC value: %lu \r\n", adc_val, dac_val);
		HAL_DAC_SetValue(&hdac1, DAC_CHANNEL_1, DAC_ALIGN_12B_R, dac_val);
	}
	#endif //DIRECT_ADC_TO_DAC
}

/**
  * @brief  Clears the ADC sample buffer
  * @param  None
  * @retval None
  */
void reset_adc_samples (void)
{
/* No need to reset the adc_readings array */
	adc_average_updated = false; //signals to other functions that adc_averaged_val shouldn't be read
	adc_sample_no = 0; //reset cyclical sample counter
	adc_readings_total = 0; //zeroes the total counter
	sample_count=0; //reset the main ADC sample counter
}

/**
  * @brief  Preparation for tuning laser frequency
  * @param  None
  * @retval None
  */
void system_mode_laser_tuning (void)
{
	stop_MW_operation(); //resets MW timers, sets MW_invalid pin low (to ensure ADC sample pulse) and sets correct MW state
	//MW_invalid low to ensure sample pulse is generated - not strictly needed in FPGA state 0
	//HAL_GPIO_WritePin(MW_INVALID_GPIO_Port, MW_INVALID_Pin, GPIO_PIN_RESET); //Sets MW_invalid pin low
	//laser_tuning (FPGA input pin 18) must be high for probe on and MW off
	HAL_GPIO_WritePin(LASER_TUNING_GPIO_Port, LASER_TUNING_Pin, GPIO_PIN_SET); // Laser_tuning output high
	reset_adc_samples(); //reset ADC samples including sample count
}

/**
  * @brief  Measure POP cycle time
  * @param  None
  * @retval None
  */
void measure_POP_cycle_time (void)
{
	/* Measure the period of a POP cycle *AFTER* the ADC has been initialised
	 * Should be performed before calculating sweep settings
	 */
	stop_laser_tuning(); //ensure MW_timer not being used and laser tuning pin high
	start_timer(SWEEP_TIMER); //Using sweep timer for 3s timeout
	start_POP_cycle_calibration(true);
	//loop here until period of POP cycle has been measured or 3s has elapsed
	//When correctly connected, POP cycle measurement should take 1.3s
	while (!POP_period_us && (check_timer(SWEEP_TIMER) < 3000000)) {
		MW_update();
//		printf("POP_period_us %lu, SWEEP_TIMER value %lu \r\n", POP_period_us, check_timer(SWEEP_TIMER));
	}
//	printf("Finished loop - POP_period_us %lu, SWEEP_TIMER value %lu \r\n", POP_period_us, check_timer(SWEEP_TIMER));
	stop_timer(SWEEP_TIMER); //stop SWEEP_TIMER
	if (!POP_period_us) {//if the calibration loop timed out
		printf("WARNING - STM32 is not receiving a periodic sample from the FPGA \r\n");
	}
	stop_MW_operation(); //release MW_SWEEP timer and ensure MW_INVALID is cleared
}

/**
  * @brief  Preparation for POP inc. MW tuning
  * @param  None
  * @retval None
  */
void system_mode_MW_tuning (void)
{
	//MW_invalid low to ensure sample pulse is generated - not strictly needed in FPGA state 0
	HAL_GPIO_WritePin(MW_INVALID_GPIO_Port, MW_INVALID_Pin, GPIO_PIN_RESET); //Sets MW_invalid pin low
	//laser_tuning (FPGA input pin 18) must be low for POP
	HAL_GPIO_WritePin(LASER_TUNING_GPIO_Port, LASER_TUNING_Pin, GPIO_PIN_RESET); // Laser_tuning output low
	reset_adc_samples(); //reset ADC samples including sample count
}

/* USER CODE END 4 */

/* MPU Configuration */

void MPU_Config(void)
{
  MPU_Region_InitTypeDef MPU_InitStruct = {0};

  /* Disables the MPU */
  HAL_MPU_Disable();

  /** Initializes and configures the Region and the memory to be protected
  */
  MPU_InitStruct.Enable = MPU_REGION_ENABLE;
  MPU_InitStruct.Number = MPU_REGION_NUMBER0;
  MPU_InitStruct.BaseAddress = 0x0;
  MPU_InitStruct.Size = MPU_REGION_SIZE_4GB;
  MPU_InitStruct.SubRegionDisable = 0x87;
  MPU_InitStruct.TypeExtField = MPU_TEX_LEVEL0;
  MPU_InitStruct.AccessPermission = MPU_REGION_NO_ACCESS;
  MPU_InitStruct.DisableExec = MPU_INSTRUCTION_ACCESS_DISABLE;
  MPU_InitStruct.IsShareable = MPU_ACCESS_SHAREABLE;
  MPU_InitStruct.IsCacheable = MPU_ACCESS_NOT_CACHEABLE;
  MPU_InitStruct.IsBufferable = MPU_ACCESS_NOT_BUFFERABLE;

  HAL_MPU_ConfigRegion(&MPU_InitStruct);

  /** Initializes and configures the Region and the memory to be protected
  */
  MPU_InitStruct.Number = MPU_REGION_NUMBER1;
  MPU_InitStruct.BaseAddress = 0x30020000;
  MPU_InitStruct.Size = MPU_REGION_SIZE_128KB;
  MPU_InitStruct.SubRegionDisable = 0x0;
  MPU_InitStruct.TypeExtField = MPU_TEX_LEVEL1;
  MPU_InitStruct.AccessPermission = MPU_REGION_FULL_ACCESS;
  MPU_InitStruct.IsShareable = MPU_ACCESS_NOT_SHAREABLE;

  HAL_MPU_ConfigRegion(&MPU_InitStruct);

  /** Initializes and configures the Region and the memory to be protected
  */
  MPU_InitStruct.Number = MPU_REGION_NUMBER2;
  MPU_InitStruct.BaseAddress = 0x30040000;
  MPU_InitStruct.Size = MPU_REGION_SIZE_512B;
  MPU_InitStruct.TypeExtField = MPU_TEX_LEVEL0;
  MPU_InitStruct.IsShareable = MPU_ACCESS_SHAREABLE;
  MPU_InitStruct.IsBufferable = MPU_ACCESS_BUFFERABLE;

  HAL_MPU_ConfigRegion(&MPU_InitStruct);
  /* Enables the MPU */
  HAL_MPU_Enable(MPU_PRIVILEGED_DEFAULT);

}

void Error_Handler(void)
{
  /* USER CODE BEGIN Error_Handler_Debug */
	__disable_irq();

	printf("Error handler routine called\r\n");

	/* Disable the AOM */
	HAL_HRTIM_WaveformOutputStop(&hhrtim, HRTIM_OUTPUT_TA1 | HRTIM_OUTPUT_TA2 | HRTIM_OUTPUT_TE1);
	HAL_HRTIM_WaveformCounterStop_IT(&hhrtim, HRTIM_TIMERID_TIMER_A | HRTIM_TIMERID_TIMER_E);

	/* Power down the synthesiser */
	HAL_GPIO_WritePin(REG_EN_GPIO_Port, REG_EN_Pin, 0);

	while (1) {
		HAL_GPIO_TogglePin(LD3_GPIO_Port, LD3_Pin); //toggle red LED
		timer_delay(SLOW_TIMER, ERROR_LED_DELAY);
	}
  /* USER CODE END Error_Handler_Debug */
}
